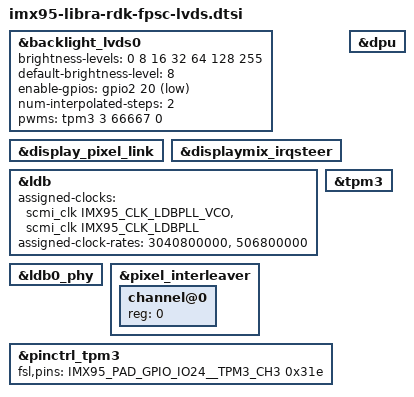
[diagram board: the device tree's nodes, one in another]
// SPDX-License-Identifier: (GPL-2.0-or-later OR MIT)
/*
 * Copyright (C) 2025 PHYTEC Messtechnik GmbH
 */

#include <dt-bindings/clock/fsl,imx95-clock.h>
#include <dt-bindings/gpio/gpio.h>

#include "imx95-pinfunc.h"

/dts-v1/;
/plugin/;

&backlight_lvds0 {
	brightness-levels = <0 8 16 32 64 128 255>;
	default-brightness-level = <8>;
	enable-gpios = <&gpio2 20 GPIO_ACTIVE_LOW>;
	num-interpolated-steps = <2>;
	pwms = <&tpm3 3 66667 0>;
	status = "okay";
};

&display_pixel_link {
	status = "okay";
};

&displaymix_irqsteer {
	status = "okay";
};

&dpu {
	status = "okay";
};

&ldb {
	/* 72.4 MHz Pixel clock */
	assigned-clocks = <&scmi_clk IMX95_CLK_LDBPLL_VCO>,
			  <&scmi_clk IMX95_CLK_LDBPLL>;
	assigned-clock-rates = <3040800000>, <506800000>;
	status = "okay";
};

&ldb0_phy {
	status = "okay";
};

&pixel_interleaver {
        #address-cells = <1>;
        #size-cells = <0>;
        status = "okay";

        channel@0 {
                reg = <0>;
                status = "okay";
        };
};

&tpm3 {
	status = "okay";
};

/* activate pull up */
&pinctrl_tpm3 {
	fsl,pins = <
		IMX95_PAD_GPIO_IO24__TPM3_CH3     0x31e   /* PWM1 */
	>;
};
